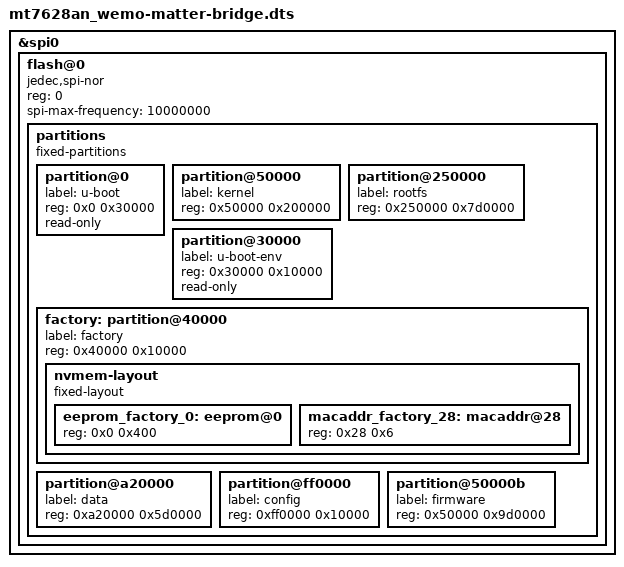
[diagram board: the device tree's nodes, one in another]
// SPDX-License-Identifier: GPL-2.0-or-later OR MIT

#include "mt7628an_wemo-matter-bridge.dtsi"

&spi0 {
	status = "okay";

	flash@0 {
		compatible = "jedec,spi-nor";
		reg = <0>;
		spi-max-frequency = <10000000>;

		partitions {
			compatible = "fixed-partitions";
			#address-cells = <1>;
			#size-cells = <1>;

			partition@0 {
				label = "u-boot";
				reg = <0x0 0x30000>;
				read-only;
			};

			partition@50000 {
				label = "kernel";
				reg = <0x50000 0x200000>;
			};

			partition@250000 {
				label = "rootfs";
				reg = <0x250000 0x7d0000>;
			};

			partition@30000 {
				label = "u-boot-env";
				reg = <0x30000 0x10000>;
				read-only;
			};

			factory: partition@40000 {
				label = "factory";
				reg = <0x40000 0x10000>;

				nvmem-layout {
					compatible = "fixed-layout";
					#address-cells = <1>;
					#size-cells = <1>;

					eeprom_factory_0: eeprom@0 {
						reg = <0x0 0x400>;
					};

					macaddr_factory_28: macaddr@28 {
						reg = <0x28 0x6>;
					};
				};
			};

			partition@a20000 {
				label = "data";
				reg = <0xa20000 0x5d0000>;
			};

			partition@ff0000 {
				label = "config";
				reg = <0xff0000 0x10000>;
			};

			partition@50000b {
				label = "firmware";
				reg = <0x50000 0x9d0000>;
			};
		};
	};
};
